# MKL28T7_CORE1 register map
Vendor: Freescale Semiconductor, Inc.; Series: Kinetis_L; File version: 1.6
CPU: CM0PLUS r0p0, little endian, no MPU, no FPU, VTOR, 2 interrupt priority bits
Registers are 32-bit, read-write, reset 0x0 unless marked. A register's access mark holds for its fields unless they carry their own. Offsets are from the block's base; [hi:lo] are bit positions; {n}, {i} and the like mark numbered series; 'fields as' and 'values as' point back to an identical list.

## INTMUX0 — Interrupt Multiplexer
Base 0x40024000; register names take the prefix INTMUX0_
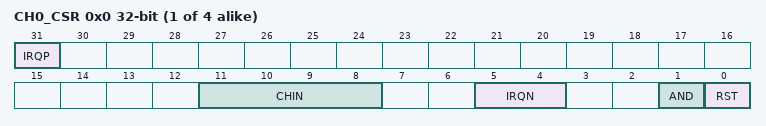
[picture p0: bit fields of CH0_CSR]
{0x0+0x40*i} CH{i}_CSR (i=0..3) — Channel n Control Status Register
  [31] IRQP ro — Channel Interrupt Request Pending
    0=No interrupt is pending; 1=The interrupt output of this channel is pending
  [11:8] CHIN ro — Channel Instance Number
  [5:4] IRQN ro — Channel Input Number
    0=32 interrupt inputs
  [1] AND — Logic AND
    0=Logic OR all enabled interrupt inputs; 1=Logic AND all enabled interrupt inputs
  [0] RST — Software Reset
    0=No operation; 1=Perform a software reset on this channel
{0x4+0x40*i} CH{i}_VEC (i=0..3) ro — Channel n Vector Number Register
  [13:2] VECN — Vector Number
{0x10+0x40*i} CH{i}_IER_31_0 (i=0..3) — Channel n Interrupt Enable Register
  [31:0] INTE — Interrupt Enable
    0=Interrupt is disabled; 1=Interrupt is enabled
{0x20+0x40*i} CH{i}_IPR_31_0 (i=0..3) ro — Channel n Interrupt Pending Register
  [31:0] INTP — Interrupt Pending
    0=No interrupt; 1=Interrupt is pending

## INTMUX1 — Interrupt Multiplexer
Base 0x400A4000; register names take the prefix INTMUX1_
Registers as INTMUX0.

## TRGMUX0
Base 0x40027000
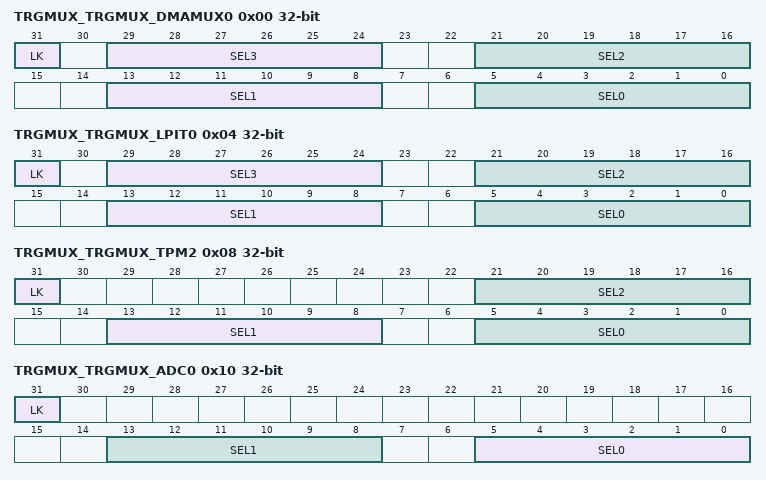
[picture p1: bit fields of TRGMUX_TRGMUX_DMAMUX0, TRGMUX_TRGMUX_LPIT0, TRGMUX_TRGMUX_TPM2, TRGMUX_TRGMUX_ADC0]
0x00 TRGMUX_TRGMUX_DMAMUX0 — TRGMUX TRGCFG Register
  [31] LK — Enable
    0=Register can be written; 1=Register cannot be written until the next system Reset
  [8n+5:8n] SEL{n} (n=0..3) — Trigger MUX Input {n} Source Select
0x04 TRGMUX_TRGMUX_LPIT0 — TRGMUX TRGCFG Register
  fields as TRGMUX_TRGMUX_DMAMUX0
0x08 TRGMUX_TRGMUX_TPM2 — TRGMUX TRGCFG Register
  [31] LK — Enable
    values as TRGMUX_TRGMUX_DMAMUX0.LK
  [21:16] SEL2 — Trigger MUX Input 2 Source Select
  [13:8] SEL1 — Trigger MUX Input 1 Source Select
  [5:0] SEL0 — Trigger MUX Input 0 Source Select
0x10 TRGMUX_TRGMUX_ADC0 — TRGMUX TRGCFG Register
  [31] LK — Enable
    values as TRGMUX_TRGMUX_DMAMUX0.LK
  [13:8] SEL1 — Trigger MUX Input 1 Source Select
  [5:0] SEL0 — Trigger MUX Input 0 Source Select
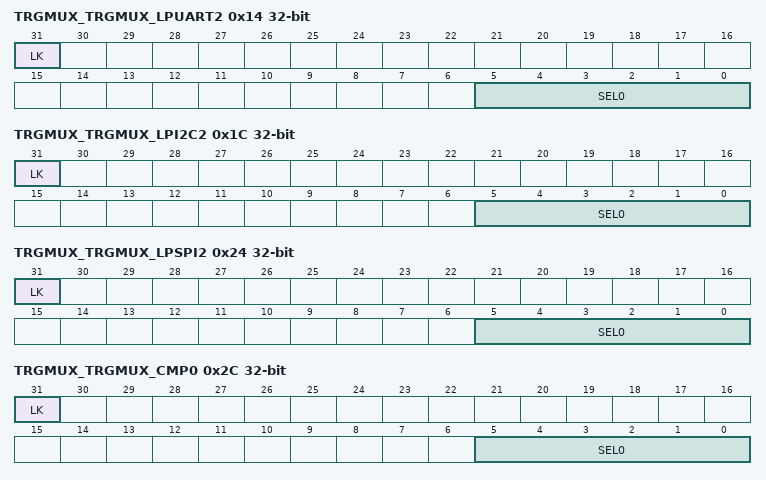
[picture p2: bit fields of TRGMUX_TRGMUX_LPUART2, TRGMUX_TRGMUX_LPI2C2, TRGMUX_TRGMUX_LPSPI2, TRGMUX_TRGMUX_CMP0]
0x14 TRGMUX_TRGMUX_LPUART2 — TRGMUX TRGCFG Register
  [31] LK — Enable
    values as TRGMUX_TRGMUX_DMAMUX0.LK
  [5:0] SEL0 — Trigger MUX Input 0 Source Select
0x1C TRGMUX_TRGMUX_LPI2C2 — TRGMUX TRGCFG Register
  fields as TRGMUX_TRGMUX_LPUART2
0x24 TRGMUX_TRGMUX_LPSPI2 — TRGMUX TRGCFG Register
  fields as TRGMUX_TRGMUX_LPUART2
0x2C TRGMUX_TRGMUX_CMP0 — TRGMUX TRGCFG Register
  fields as TRGMUX_TRGMUX_LPUART2
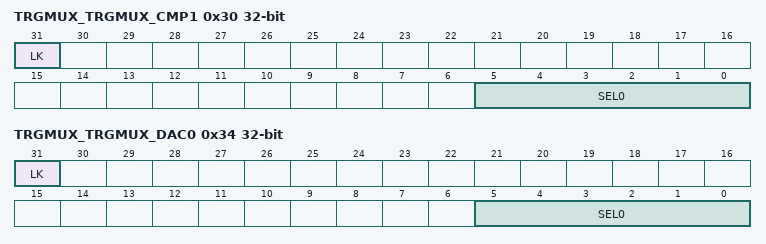
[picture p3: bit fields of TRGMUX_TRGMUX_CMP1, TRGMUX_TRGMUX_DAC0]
0x30 TRGMUX_TRGMUX_CMP1 — TRGMUX TRGCFG Register
  fields as TRGMUX_TRGMUX_LPUART2
0x34 TRGMUX_TRGMUX_DAC0 — TRGMUX TRGCFG Register
  fields as TRGMUX_TRGMUX_LPUART2

## LLWU0 — Low leakage wakeup unit
Base 0x40061000; register names take the prefix LLWU0_
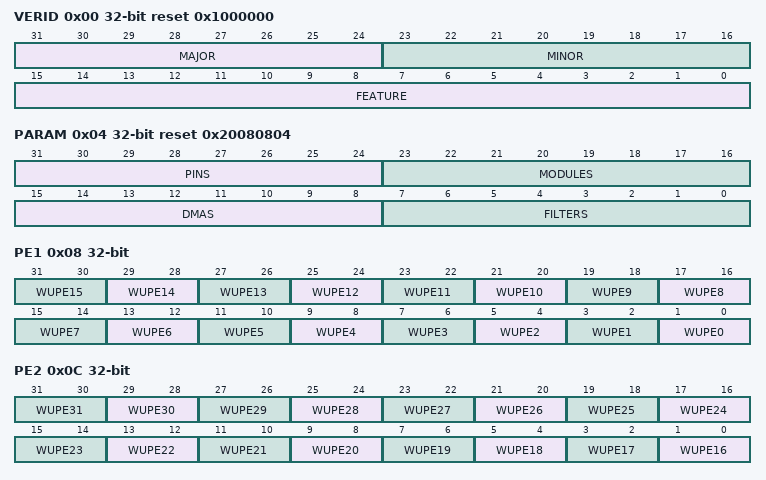
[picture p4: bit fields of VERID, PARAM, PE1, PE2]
0x00 VERID ro reset 0x1000000 — Version ID Register
  [31:24] MAJOR — Major Version Number
  [23:16] MINOR — Minor Version Number
  [15:0] FEATURE — Feature Specification Number
    0=Standard features implemented
0x04 PARAM ro reset 0x20080804 — Parameter Register
  [31:24] PINS — Pin Number
  [23:16] MODULES — Module Number
  [15:8] DMAS — DMA Number
  [7:0] FILTERS — Filter Number
0x08 PE1 — LLWU Pin Enable 1 register
  [all] fields
    0=External input pin disabled as wakeup input; 1=External input pin enabled with rising edge detection; 2=External input pin enabled with falling edge detection; 3=External input pin enabled with any change detection
  [2n+1:2n] WUPE{n} (n=0..15) — Wakeup Pin Enable For LLWU_P{n}
0x0C PE2 — LLWU Pin Enable 2 register
  [all] fields
    values as the fields of PE1
  [2n-31:2n-32] WUPE{n} (n=16..31) — Wakeup Pin Enable For LLWU_P{n}
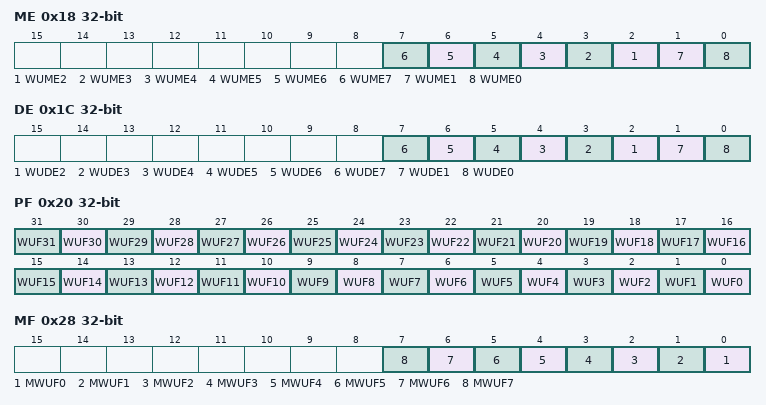
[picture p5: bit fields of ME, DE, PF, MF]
0x18 ME — LLWU Module Interrupt Enable register
  [all] fields
    0=Internal module flag not used as wakeup source; 1=Internal module flag used as wakeup source
  [n] WUME{n} (n=2..7) — Wakeup Module Enable For Module {n}
  [1] WUME1 — Wakeup Module Enable for Module 1
  [0] WUME0 — Wakeup Module Enable For Module 0
0x1C DE — LLWU Module DMA Enable register
  [all] fields
    0=Internal module request not used as a DMA wakeup source; 1=Internal module request used as a DMA wakeup source
  [n] WUDE{n} (n=2..7) — DMA Wakeup Enable For Module {n}
  [1] WUDE1 — DMA Wakeup Enable for Module 1
  [0] WUDE0 — DMA Wakeup Enable For Module 0
0x20 PF — LLWU Pin Flag register
  [n] WUF{n} (n=0..31) — Wakeup Flag For LLWU_P{n}
    0=LLWU_P{n} input was not a wakeup source; 1=LLWU_P{n} input was a wakeup source
0x28 MF ro — LLWU Module Interrupt Flag register
  [n] MWUF{n} (n=0..7) — Wakeup flag For module {n}
    0=Module {n} input was not a wakeup source; 1=Module {n} input was a wakeup source
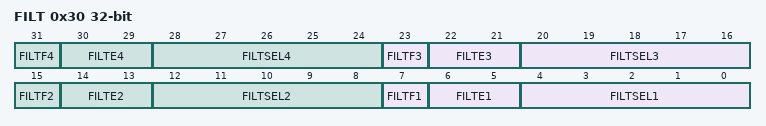
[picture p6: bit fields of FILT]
0x30 FILT — LLWU Pin Filter register
  [8n-1] FILTF{n} (n=1..4) — Filter {n} Flag
    0=Pin Filter 1 was not a wakeup source; 1=Pin Filter 1 was a wakeup source
  [8n-2:8n-3] FILTE{n} (n=1..4) — Filter {n} Enable
    0=Filter disabled; 1=Filter posedge detect enabled; 2=Filter negedge detect enabled; 3=Filter any edge detect enabled
  [8n-4:8n-8] FILTSEL{n} (n=1..4) — Filter {n} Pin Select
    0=Select LLWU_P0 for filter; 31=Select LLWU_P31 for filter

## LLWU1 — Low leakage wakeup unit
Base 0x400E1000; register names take the prefix LLWU1_
Registers as LLWU0.

## Notices in the file
Redistribution and use in source and binary forms, with or without modification,
are permitted provided that the following conditions are met:
o Redistributions of source code must retain the above copyright notice, this list
of conditions and the following disclaimer.
o Redistributions in binary form must reproduce the above copyright notice, this
list of conditions and the following disclaimer in the documentation and/or
other materials provided with the distribution.
o Neither the name of Freescale Semiconductor, Inc. nor the names of its
contributors may be used to endorse or promote products derived from this
software without specific prior written permission.
THIS SOFTWARE IS PROVIDED BY THE COPYRIGHT HOLDERS AND CONTRIBUTORS "AS IS" AND
ANY EXPRESS OR IMPLIED WARRANTIES, INCLUDING, BUT NOT LIMITED TO, THE IMPLIED
WARRANTIES OF MERCHANTABILITY AND FITNESS FOR A PARTICULAR PURPOSE ARE
DISCLAIMED. IN NO EVENT SHALL THE COPYRIGHT HOLDER OR CONTRIBUTORS BE LIABLE FOR
ANY DIRECT, INDIRECT, INCIDENTAL, SPECIAL, EXEMPLARY, OR CONSEQUENTIAL DAMAGES
(INCLUDING, BUT NOT LIMITED TO, PROCUREMENT OF SUBSTITUTE GOODS OR SERVICES;
LOSS OF USE, DATA, OR PROFITS; OR BUSINESS INTERRUPTION) HOWEVER CAUSED AND ON
ANY THEORY OF LIABILITY, WHETHER IN CONTRACT, STRICT LIABILITY, OR TORT
(INCLUDING NEGLIGENCE OR OTHERWISE) ARISING IN ANY WAY OUT OF THE USE OF THIS
SOFTWARE, EVEN IF ADVISED OF THE POSSIBILITY OF SUCH DAMAGE.
